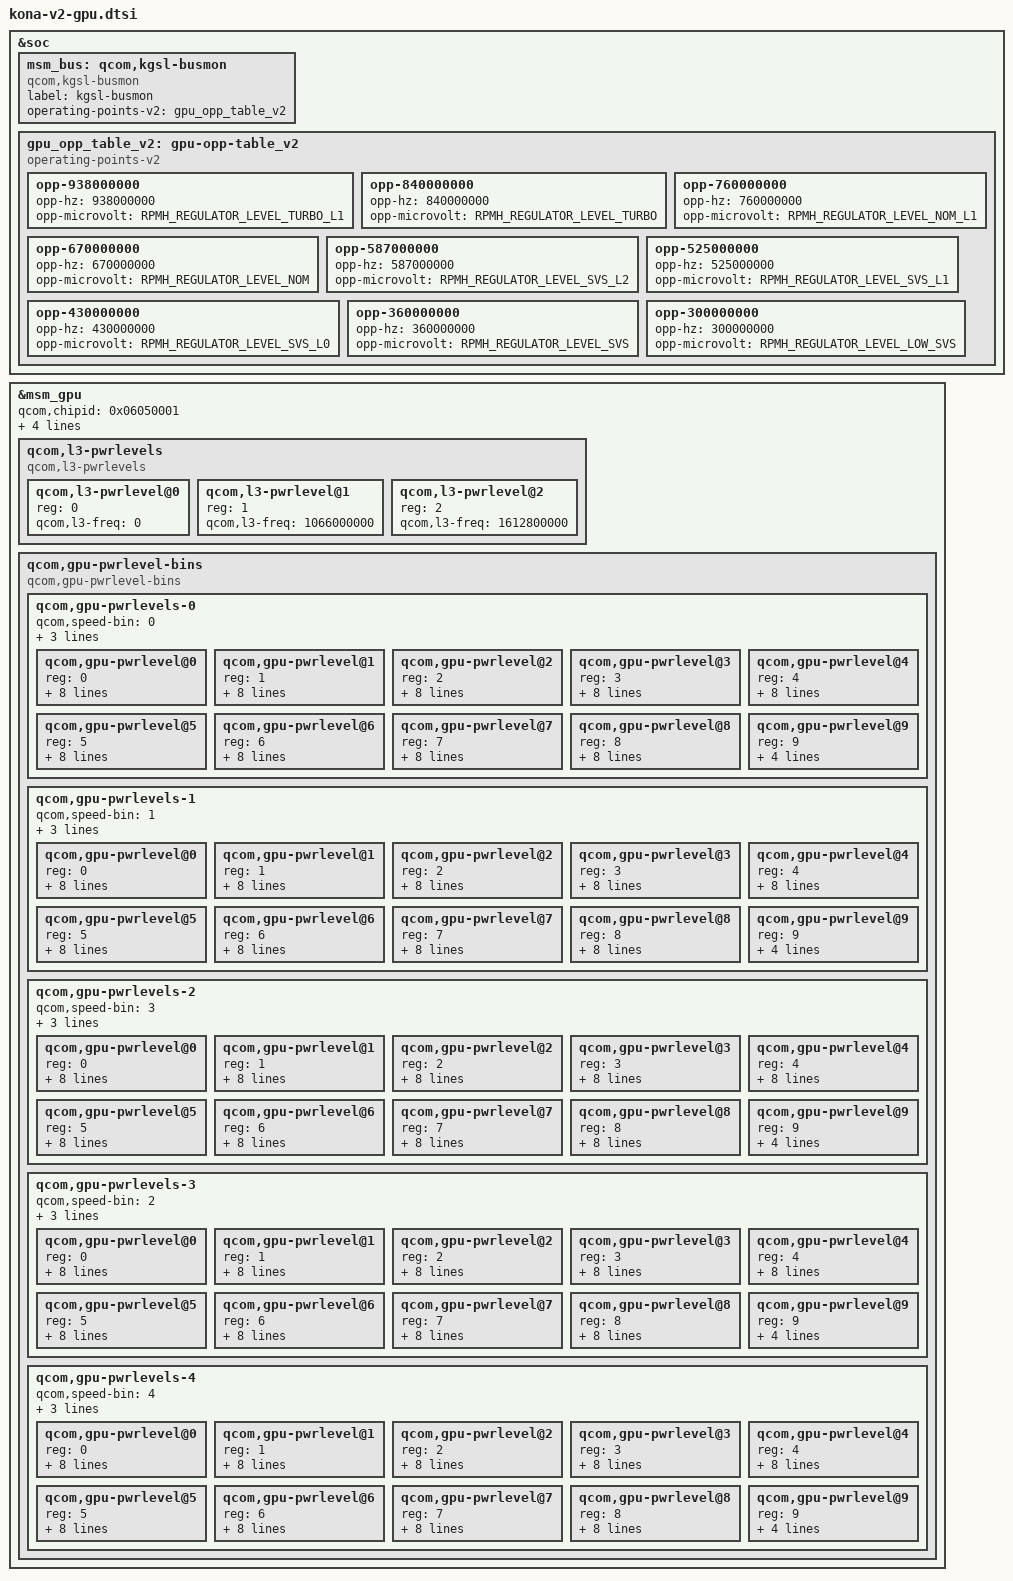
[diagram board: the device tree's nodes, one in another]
&soc {
	msm_bus: qcom,kgsl-busmon {
		label = "kgsl-busmon";
		compatible = "qcom,kgsl-busmon";
		operating-points-v2 = <&gpu_opp_table_v2>;
	};

	gpu_opp_table_v2: gpu-opp-table_v2 {
		compatible = "operating-points-v2";

		opp-938000000 {
			opp-hz = /bits/ 64 <938000000>;
			opp-microvolt = <RPMH_REGULATOR_LEVEL_TURBO_L1>;
		};
		opp-840000000 {
			opp-hz = /bits/ 64 <840000000>;
			opp-microvolt = <RPMH_REGULATOR_LEVEL_TURBO>;
		};
		opp-760000000 {
			opp-hz = /bits/ 64 <760000000>;
			opp-microvolt = <RPMH_REGULATOR_LEVEL_NOM_L1>;
		};
		opp-670000000 {
			opp-hz = /bits/ 64 <670000000>;
			opp-microvolt = <RPMH_REGULATOR_LEVEL_NOM>;
		};
		opp-587000000 {
			opp-hz = /bits/ 64 <587000000>;
			opp-microvolt = <RPMH_REGULATOR_LEVEL_SVS_L2>;
		};
		opp-525000000 {
			opp-hz = /bits/ 64 <525000000>;
			opp-microvolt = <RPMH_REGULATOR_LEVEL_SVS_L1>;
		};
		opp-430000000 {
			opp-hz = /bits/ 64 <430000000>;
			opp-microvolt = <RPMH_REGULATOR_LEVEL_SVS_L0>;
		};
		opp-360000000 {
			opp-hz = /bits/ 64 <360000000>;
			opp-microvolt = <RPMH_REGULATOR_LEVEL_SVS>;
		};
		opp-300000000 {
			opp-hz = /bits/ 64 <300000000>;
			opp-microvolt = <RPMH_REGULATOR_LEVEL_LOW_SVS>;
		};
	};
};

&msm_gpu {
	qcom,chipid = <0x06050001>;

	qcom,enable-ca-jump;
	qcom,ca-busy-penalty = <9000>;
	qcom,enable-midframe-timer;

	/* GPU OPP data */
	operating-points-v2 = <&gpu_opp_table_v2>;

	/delete-property/qcom,initial-pwrlevel;
	/delete-node/qcom,gpu-pwrlevels;
	/delete-node/qcom,l3-pwrlevels;

	/* L3 vote levels tuned for the higher Kona V2 GPU bins */
	qcom,l3-pwrlevels {
		#address-cells = <1>;
		#size-cells = <0>;
		compatible = "qcom,l3-pwrlevels";

		qcom,l3-pwrlevel@0 {
			reg = <0>;
			qcom,l3-freq = <0>;
		};

		qcom,l3-pwrlevel@1 {
			reg = <1>;
			qcom,l3-freq = <1066000000>;
		};

		qcom,l3-pwrlevel@2 {
			reg = <2>;
			qcom,l3-freq = <1612800000>;
		};
	};

	/* Power levels bins */
	qcom,gpu-pwrlevel-bins {
		compatible="qcom,gpu-pwrlevel-bins";
		#address-cells = <1>;
		#size-cells = <0>;

		qcom,gpu-pwrlevels-0 {
			#address-cells = <1>;
			#size-cells = <0>;
			qcom,speed-bin = <0>;
			/* Start and resume at the lowest non-zero GPU OPP. */
			qcom,initial-pwrlevel = <8>;
			qcom,throttle-pwrlevel = <0>;
			qcom,ca-target-pwrlevel = <1>;

			qcom,gpu-pwrlevel@0 {
				reg = <0>;
				qcom,gpu-freq = <938000000>;
				qcom,bus-freq-ddr7 = <13>;
				qcom,bus-min-ddr7 = <10>;
				qcom,bus-max-ddr7 = <13>;

				qcom,bus-freq-ddr8 = <13>;
				qcom,bus-min-ddr8 = <10>;
				qcom,bus-max-ddr8 = <13>;

				qcom,acd-level = <0x802b5ffd>;
			};

			qcom,gpu-pwrlevel@1 {
				reg = <1>;
				qcom,gpu-freq = <840000000>;
				qcom,bus-freq-ddr7 = <13>;
				qcom,bus-min-ddr7 = <10>;
				qcom,bus-max-ddr7 = <13>;

				qcom,bus-freq-ddr8 = <13>;
				qcom,bus-min-ddr8 = <10>;
				qcom,bus-max-ddr8 = <13>;

				qcom,acd-level = <0x802b5ffd>;
			};

			qcom,gpu-pwrlevel@2 {
				reg = <2>;
				qcom,gpu-freq = <760000000>;
				qcom,bus-freq-ddr7 = <13>;
				qcom,bus-min-ddr7 = <10>;
				qcom,bus-max-ddr7 = <13>;

				qcom,bus-freq-ddr8 = <13>;
				qcom,bus-min-ddr8 = <10>;
				qcom,bus-max-ddr8 = <13>;

				qcom,acd-level = <0x802b5ffd>;
			};

			qcom,gpu-pwrlevel@3 {
				reg = <3>;
				qcom,gpu-freq = <670000000>;
				qcom,bus-freq-ddr7 = <13>;
				qcom,bus-min-ddr7 = <10>;
				qcom,bus-max-ddr7 = <13>;

				qcom,bus-freq-ddr8 = <13>;
				qcom,bus-min-ddr8 = <10>;
				qcom,bus-max-ddr8 = <13>;

				qcom,acd-level = <0x802b5ffd>;
			};

			qcom,gpu-pwrlevel@4 {
				reg = <4>;
				qcom,gpu-freq = <587000000>;
				qcom,bus-freq-ddr7 = <12>;
				qcom,bus-min-ddr7 = <10>;
				qcom,bus-max-ddr7 = <13>;

				qcom,bus-freq-ddr8 = <12>;
				qcom,bus-min-ddr8 = <10>;
				qcom,bus-max-ddr8 = <13>;

				qcom,acd-level = <0x802b5ffd>;
			};

			qcom,gpu-pwrlevel@5 {
				reg = <5>;
				qcom,gpu-freq = <525000000>;
				qcom,bus-freq-ddr7 = <11>;
				qcom,bus-min-ddr7 = <9>;
				qcom,bus-max-ddr7 = <13>;

				qcom,bus-freq-ddr8 = <11>;
				qcom,bus-min-ddr8 = <9>;
				qcom,bus-max-ddr8 = <13>;

				qcom,acd-level = <0x802b5ffd>;
			};

			qcom,gpu-pwrlevel@6 {
				reg = <6>;
				qcom,gpu-freq = <430000000>;
				qcom,bus-freq-ddr7 = <10>;
				qcom,bus-min-ddr7 = <10>;
				qcom,bus-max-ddr7 = <12>;

				qcom,bus-freq-ddr8 = <10>;
				qcom,bus-min-ddr8 = <10>;
				qcom,bus-max-ddr8 = <12>;

				qcom,acd-level = <0xa02b5ffd>;
			};

			qcom,gpu-pwrlevel@7 {
				reg = <7>;
				qcom,gpu-freq = <360000000>;
				qcom,bus-freq-ddr7 = <10>;
				qcom,bus-min-ddr7 = <10>;
				qcom,bus-max-ddr7 = <12>;

				qcom,bus-freq-ddr8 = <10>;
				qcom,bus-min-ddr8 = <10>;
				qcom,bus-max-ddr8 = <12>;

				qcom,acd-level = <0xa02b5ffd>;
			};

			qcom,gpu-pwrlevel@8 {
				reg = <8>;
				qcom,gpu-freq = <300000000>;
				qcom,bus-freq-ddr7 = <9>;
				qcom,bus-min-ddr7 = <8>;
				qcom,bus-max-ddr7 = <11>;

				qcom,bus-freq-ddr8 = <9>;
				qcom,bus-min-ddr8 = <8>;
				qcom,bus-max-ddr8 = <11>;

				qcom,acd-level = <0xa02b5ffd>;
			};

			qcom,gpu-pwrlevel@9 {
				reg = <9>;
				qcom,gpu-freq = <0>;
				qcom,bus-freq = <1>;
				qcom,bus-min = <1>;
				qcom,bus-max = <1>;
			};
		};

		qcom,gpu-pwrlevels-1 {
			#address-cells = <1>;
			#size-cells = <0>;
			qcom,speed-bin = <1>;
			qcom,initial-pwrlevel = <8>;
			qcom,throttle-pwrlevel = <1>;
			qcom,ca-target-pwrlevel = <4>;

			qcom,gpu-pwrlevel@0 {
				reg = <0>;
				qcom,gpu-freq = <938000000>;
				qcom,bus-freq-ddr7 = <13>;
				qcom,bus-min-ddr7 = <11>;
				qcom,bus-max-ddr7 = <13>;

				qcom,bus-freq-ddr8 = <13>;
				qcom,bus-min-ddr8 = <11>;
				qcom,bus-max-ddr8 = <13>;

				qcom,acd-level = <0x802b5ffd>;
			};

			qcom,gpu-pwrlevel@1 {
				reg = <1>;
				qcom,gpu-freq = <840000000>;
				qcom,bus-freq-ddr7 = <13>;
				qcom,bus-min-ddr7 = <10>;
				qcom,bus-max-ddr7 = <13>;

				qcom,bus-freq-ddr8 = <13>;
				qcom,bus-min-ddr8 = <10>;
				qcom,bus-max-ddr8 = <13>;

				qcom,acd-level = <0x802b5ffd>;
			};

			qcom,gpu-pwrlevel@2 {
				reg = <2>;
				qcom,gpu-freq = <760000000>;
				qcom,bus-freq-ddr7 = <13>;
				qcom,bus-min-ddr7 = <10>;
				qcom,bus-max-ddr7 = <13>;

				qcom,bus-freq-ddr8 = <13>;
				qcom,bus-min-ddr8 = <10>;
				qcom,bus-max-ddr8 = <13>;

				qcom,acd-level = <0x802b5ffd>;
			};

			qcom,gpu-pwrlevel@3 {
				reg = <3>;
				qcom,gpu-freq = <670000000>;
				qcom,bus-freq-ddr7 = <13>;
				qcom,bus-min-ddr7 = <10>;
				qcom,bus-max-ddr7 = <13>;

				qcom,bus-freq-ddr8 = <13>;
				qcom,bus-min-ddr8 = <10>;
				qcom,bus-max-ddr8 = <13>;

				qcom,acd-level = <0x802b5ffd>;
			};

			qcom,gpu-pwrlevel@4 {
				reg = <4>;
				qcom,gpu-freq = <587000000>;
				qcom,bus-freq-ddr7 = <12>;
				qcom,bus-min-ddr7 = <10>;
				qcom,bus-max-ddr7 = <13>;

				qcom,bus-freq-ddr8 = <12>;
				qcom,bus-min-ddr8 = <10>;
				qcom,bus-max-ddr8 = <13>;

				qcom,acd-level = <0x802b5ffd>;
			};

			qcom,gpu-pwrlevel@5 {
				reg = <5>;
				qcom,gpu-freq = <525000000>;
				qcom,bus-freq-ddr7 = <11>;
				qcom,bus-min-ddr7 = <9>;
				qcom,bus-max-ddr7 = <13>;

				qcom,bus-freq-ddr8 = <11>;
				qcom,bus-min-ddr8 = <9>;
				qcom,bus-max-ddr8 = <13>;

				qcom,acd-level = <0x802b5ffd>;
			};

			qcom,gpu-pwrlevel@6 {
				reg = <6>;
				qcom,gpu-freq = <430000000>;
				qcom,bus-freq-ddr7 = <10>;
				qcom,bus-min-ddr7 = <10>;
				qcom,bus-max-ddr7 = <12>;

				qcom,bus-freq-ddr8 = <10>;
				qcom,bus-min-ddr8 = <10>;
				qcom,bus-max-ddr8 = <12>;

				qcom,acd-level = <0xa02b5ffd>;
			};

			qcom,gpu-pwrlevel@7 {
				reg = <7>;
				qcom,gpu-freq = <360000000>;
				qcom,bus-freq-ddr7 = <10>;
				qcom,bus-min-ddr7 = <10>;
				qcom,bus-max-ddr7 = <12>;

				qcom,bus-freq-ddr8 = <10>;
				qcom,bus-min-ddr8 = <10>;
				qcom,bus-max-ddr8 = <12>;

				qcom,acd-level = <0xa02b5ffd>;
			};

			qcom,gpu-pwrlevel@8 {
				reg = <8>;
				qcom,gpu-freq = <300000000>;
				qcom,bus-freq-ddr7 = <9>;
				qcom,bus-min-ddr7 = <8>;
				qcom,bus-max-ddr7 = <11>;

				qcom,bus-freq-ddr8 = <9>;
				qcom,bus-min-ddr8 = <8>;
				qcom,bus-max-ddr8 = <11>;

				qcom,acd-level = <0xa02b5ffd>;
			};

			qcom,gpu-pwrlevel@9 {
				reg = <9>;
				qcom,gpu-freq = <0>;
				qcom,bus-freq = <1>;
				qcom,bus-min = <1>;
				qcom,bus-max = <1>;
			};
		};

		qcom,gpu-pwrlevels-2 {
			#address-cells = <1>;
			#size-cells = <0>;
			qcom,speed-bin = <3>;
			qcom,initial-pwrlevel = <8>;
			qcom,throttle-pwrlevel = <1>;
			qcom,ca-target-pwrlevel = <4>;

			qcom,gpu-pwrlevel@0 {
				reg = <0>;
				qcom,gpu-freq = <938000000>;
				qcom,bus-freq-ddr7 = <13>;
				qcom,bus-min-ddr7 = <11>;
				qcom,bus-max-ddr7 = <13>;

				qcom,bus-freq-ddr8 = <13>;
				qcom,bus-min-ddr8 = <11>;
				qcom,bus-max-ddr8 = <13>;

				qcom,acd-level = <0x802b5ffd>;
			};

			qcom,gpu-pwrlevel@1 {
				reg = <1>;
				qcom,gpu-freq = <840000000>;
				qcom,bus-freq-ddr7 = <13>;
				qcom,bus-min-ddr7 = <10>;
				qcom,bus-max-ddr7 = <13>;

				qcom,bus-freq-ddr8 = <13>;
				qcom,bus-min-ddr8 = <10>;
				qcom,bus-max-ddr8 = <13>;

				qcom,acd-level = <0x802b5ffd>;
			};

			qcom,gpu-pwrlevel@2 {
				reg = <2>;
				qcom,gpu-freq = <760000000>;
				qcom,bus-freq-ddr7 = <13>;
				qcom,bus-min-ddr7 = <10>;
				qcom,bus-max-ddr7 = <13>;

				qcom,bus-freq-ddr8 = <13>;
				qcom,bus-min-ddr8 = <10>;
				qcom,bus-max-ddr8 = <13>;

				qcom,acd-level = <0x802b5ffd>;
			};

			qcom,gpu-pwrlevel@3 {
				reg = <3>;
				qcom,gpu-freq = <670000000>;
				qcom,bus-freq-ddr7 = <13>;
				qcom,bus-min-ddr7 = <10>;
				qcom,bus-max-ddr7 = <13>;

				qcom,bus-freq-ddr8 = <13>;
				qcom,bus-min-ddr8 = <10>;
				qcom,bus-max-ddr8 = <13>;

				qcom,acd-level = <0x802b5ffd>;
			};

			qcom,gpu-pwrlevel@4 {
				reg = <4>;
				qcom,gpu-freq = <587000000>;
				qcom,bus-freq-ddr7 = <12>;
				qcom,bus-min-ddr7 = <10>;
				qcom,bus-max-ddr7 = <13>;

				qcom,bus-freq-ddr8 = <12>;
				qcom,bus-min-ddr8 = <10>;
				qcom,bus-max-ddr8 = <13>;

				qcom,acd-level = <0x802b5ffd>;
			};

			qcom,gpu-pwrlevel@5 {
				reg = <5>;
				qcom,gpu-freq = <525000000>;
				qcom,bus-freq-ddr7 = <11>;
				qcom,bus-min-ddr7 = <9>;
				qcom,bus-max-ddr7 = <13>;

				qcom,bus-freq-ddr8 = <11>;
				qcom,bus-min-ddr8 = <9>;
				qcom,bus-max-ddr8 = <13>;

				qcom,acd-level = <0x802b5ffd>;
			};

			qcom,gpu-pwrlevel@6 {
				reg = <6>;
				qcom,gpu-freq = <430000000>;
				qcom,bus-freq-ddr7 = <10>;
				qcom,bus-min-ddr7 = <10>;
				qcom,bus-max-ddr7 = <12>;

				qcom,bus-freq-ddr8 = <10>;
				qcom,bus-min-ddr8 = <10>;
				qcom,bus-max-ddr8 = <12>;

				qcom,acd-level = <0xa02b5ffd>;
			};

			qcom,gpu-pwrlevel@7 {
				reg = <7>;
				qcom,gpu-freq = <360000000>;
				qcom,bus-freq-ddr7 = <10>;
				qcom,bus-min-ddr7 = <10>;
				qcom,bus-max-ddr7 = <12>;

				qcom,bus-freq-ddr8 = <10>;
				qcom,bus-min-ddr8 = <10>;
				qcom,bus-max-ddr8 = <12>;

				qcom,acd-level = <0xa02b5ffd>;
			};

			qcom,gpu-pwrlevel@8 {
				reg = <8>;
				qcom,gpu-freq = <300000000>;
				qcom,bus-freq-ddr7 = <9>;
				qcom,bus-min-ddr7 = <8>;
				qcom,bus-max-ddr7 = <11>;

				qcom,bus-freq-ddr8 = <9>;
				qcom,bus-min-ddr8 = <8>;
				qcom,bus-max-ddr8 = <11>;

				qcom,acd-level = <0xa02b5ffd>;
			};

			qcom,gpu-pwrlevel@9 {
				reg = <9>;
				qcom,gpu-freq = <0>;
				qcom,bus-freq = <1>;
				qcom,bus-min = <1>;
				qcom,bus-max = <1>;
			};
		};

		qcom,gpu-pwrlevels-3 {
			#address-cells = <1>;
			#size-cells = <0>;
			qcom,speed-bin = <2>;
			qcom,initial-pwrlevel = <8>;
			qcom,throttle-pwrlevel = <1>;
			qcom,ca-target-pwrlevel = <4>;

			qcom,gpu-pwrlevel@0 {
				reg = <0>;
				qcom,gpu-freq = <938000000>;
				qcom,bus-freq-ddr7 = <13>;
				qcom,bus-min-ddr7 = <11>;
				qcom,bus-max-ddr7 = <13>;

				qcom,bus-freq-ddr8 = <13>;
				qcom,bus-min-ddr8 = <11>;
				qcom,bus-max-ddr8 = <13>;

				qcom,acd-level = <0x802b5ffd>;
			};

			qcom,gpu-pwrlevel@1 {
				reg = <1>;
				qcom,gpu-freq = <840000000>;
				qcom,bus-freq-ddr7 = <13>;
				qcom,bus-min-ddr7 = <10>;
				qcom,bus-max-ddr7 = <13>;

				qcom,bus-freq-ddr8 = <13>;
				qcom,bus-min-ddr8 = <10>;
				qcom,bus-max-ddr8 = <13>;

				qcom,acd-level = <0x802b5ffd>;
			};

			qcom,gpu-pwrlevel@2 {
				reg = <2>;
				qcom,gpu-freq = <760000000>;
				qcom,bus-freq-ddr7 = <13>;
				qcom,bus-min-ddr7 = <10>;
				qcom,bus-max-ddr7 = <13>;

				qcom,bus-freq-ddr8 = <13>;
				qcom,bus-min-ddr8 = <10>;
				qcom,bus-max-ddr8 = <13>;

				qcom,acd-level = <0x802b5ffd>;
			};

			qcom,gpu-pwrlevel@3 {
				reg = <3>;
				qcom,gpu-freq = <670000000>;
				qcom,bus-freq-ddr7 = <13>;
				qcom,bus-min-ddr7 = <10>;
				qcom,bus-max-ddr7 = <13>;

				qcom,bus-freq-ddr8 = <13>;
				qcom,bus-min-ddr8 = <10>;
				qcom,bus-max-ddr8 = <13>;

				qcom,acd-level = <0x802b5ffd>;
			};

			qcom,gpu-pwrlevel@4 {
				reg = <4>;
				qcom,gpu-freq = <587000000>;
				qcom,bus-freq-ddr7 = <12>;
				qcom,bus-min-ddr7 = <10>;
				qcom,bus-max-ddr7 = <13>;

				qcom,bus-freq-ddr8 = <12>;
				qcom,bus-min-ddr8 = <10>;
				qcom,bus-max-ddr8 = <13>;

				qcom,acd-level = <0x802b5ffd>;
			};

			qcom,gpu-pwrlevel@5 {
				reg = <5>;
				qcom,gpu-freq = <525000000>;
				qcom,bus-freq-ddr7 = <11>;
				qcom,bus-min-ddr7 = <9>;
				qcom,bus-max-ddr7 = <13>;

				qcom,bus-freq-ddr8 = <11>;
				qcom,bus-min-ddr8 = <9>;
				qcom,bus-max-ddr8 = <13>;

				qcom,acd-level = <0x802b5ffd>;
			};

			qcom,gpu-pwrlevel@6 {
				reg = <6>;
				qcom,gpu-freq = <430000000>;
				qcom,bus-freq-ddr7 = <10>;
				qcom,bus-min-ddr7 = <10>;
				qcom,bus-max-ddr7 = <12>;

				qcom,bus-freq-ddr8 = <10>;
				qcom,bus-min-ddr8 = <10>;
				qcom,bus-max-ddr8 = <12>;

				qcom,acd-level = <0xa02b5ffd>;
			};

			qcom,gpu-pwrlevel@7 {
				reg = <7>;
				qcom,gpu-freq = <360000000>;
				qcom,bus-freq-ddr7 = <10>;
				qcom,bus-min-ddr7 = <10>;
				qcom,bus-max-ddr7 = <12>;

				qcom,bus-freq-ddr8 = <10>;
				qcom,bus-min-ddr8 = <10>;
				qcom,bus-max-ddr8 = <12>;

				qcom,acd-level = <0xa02b5ffd>;
			};

			qcom,gpu-pwrlevel@8 {
				reg = <8>;
				qcom,gpu-freq = <300000000>;
				qcom,bus-freq-ddr7 = <9>;
				qcom,bus-min-ddr7 = <8>;
				qcom,bus-max-ddr7 = <11>;

				qcom,bus-freq-ddr8 = <9>;
				qcom,bus-min-ddr8 = <8>;
				qcom,bus-max-ddr8 = <11>;

				qcom,acd-level = <0xa02b5ffd>;
			};

			qcom,gpu-pwrlevel@9 {
				reg = <9>;
				qcom,gpu-freq = <0>;
				qcom,bus-freq = <1>;
				qcom,bus-min = <1>;
				qcom,bus-max = <1>;
			};
		};

		qcom,gpu-pwrlevels-4 {
			#address-cells = <1>;
			#size-cells = <0>;
			qcom,speed-bin = <4>;
			qcom,initial-pwrlevel = <8>;
			qcom,throttle-pwrlevel = <1>;
			qcom,ca-target-pwrlevel = <4>;

			qcom,gpu-pwrlevel@0 {
				reg = <0>;
				qcom,gpu-freq = <938000000>;
				qcom,bus-freq-ddr7 = <13>;
				qcom,bus-min-ddr7 = <11>;
				qcom,bus-max-ddr7 = <13>;

				qcom,bus-freq-ddr8 = <13>;
				qcom,bus-min-ddr8 = <11>;
				qcom,bus-max-ddr8 = <13>;

				qcom,acd-level = <0x802b5ffd>;
			};

			qcom,gpu-pwrlevel@1 {
				reg = <1>;
				qcom,gpu-freq = <840000000>;
				qcom,bus-freq-ddr7 = <13>;
				qcom,bus-min-ddr7 = <10>;
				qcom,bus-max-ddr7 = <13>;

				qcom,bus-freq-ddr8 = <13>;
				qcom,bus-min-ddr8 = <10>;
				qcom,bus-max-ddr8 = <13>;

				qcom,acd-level = <0x802b5ffd>;
			};

			qcom,gpu-pwrlevel@2 {
				reg = <2>;
				qcom,gpu-freq = <760000000>;
				qcom,bus-freq-ddr7 = <13>;
				qcom,bus-min-ddr7 = <10>;
				qcom,bus-max-ddr7 = <13>;

				qcom,bus-freq-ddr8 = <13>;
				qcom,bus-min-ddr8 = <10>;
				qcom,bus-max-ddr8 = <13>;

				qcom,acd-level = <0x802b5ffd>;
			};

			qcom,gpu-pwrlevel@3 {
				reg = <3>;
				qcom,gpu-freq = <670000000>;
				qcom,bus-freq-ddr7 = <13>;
				qcom,bus-min-ddr7 = <10>;
				qcom,bus-max-ddr7 = <13>;

				qcom,bus-freq-ddr8 = <13>;
				qcom,bus-min-ddr8 = <10>;
				qcom,bus-max-ddr8 = <13>;

				qcom,acd-level = <0x802b5ffd>;
			};

			qcom,gpu-pwrlevel@4 {
				reg = <4>;
				qcom,gpu-freq = <587000000>;
				qcom,bus-freq-ddr7 = <12>;
				qcom,bus-min-ddr7 = <10>;
				qcom,bus-max-ddr7 = <13>;

				qcom,bus-freq-ddr8 = <12>;
				qcom,bus-min-ddr8 = <10>;
				qcom,bus-max-ddr8 = <13>;

				qcom,acd-level = <0x802b5ffd>;
			};

			qcom,gpu-pwrlevel@5 {
				reg = <5>;
				qcom,gpu-freq = <525000000>;
				qcom,bus-freq-ddr7 = <11>;
				qcom,bus-min-ddr7 = <9>;
				qcom,bus-max-ddr7 = <13>;

				qcom,bus-freq-ddr8 = <11>;
				qcom,bus-min-ddr8 = <9>;
				qcom,bus-max-ddr8 = <13>;

				qcom,acd-level = <0x802b5ffd>;
			};

			qcom,gpu-pwrlevel@6 {
				reg = <6>;
				qcom,gpu-freq = <430000000>;
				qcom,bus-freq-ddr7 = <10>;
				qcom,bus-min-ddr7 = <10>;
				qcom,bus-max-ddr7 = <12>;

				qcom,bus-freq-ddr8 = <10>;
				qcom,bus-min-ddr8 = <10>;
				qcom,bus-max-ddr8 = <12>;

				qcom,acd-level = <0xa02b5ffd>;
			};

			qcom,gpu-pwrlevel@7 {
				reg = <7>;
				qcom,gpu-freq = <360000000>;
				qcom,bus-freq-ddr7 = <10>;
				qcom,bus-min-ddr7 = <10>;
				qcom,bus-max-ddr7 = <12>;

				qcom,bus-freq-ddr8 = <10>;
				qcom,bus-min-ddr8 = <10>;
				qcom,bus-max-ddr8 = <12>;

				qcom,acd-level = <0xa02b5ffd>;
			};

			qcom,gpu-pwrlevel@8 {
				reg = <8>;
				qcom,gpu-freq = <300000000>;
				qcom,bus-freq-ddr7 = <9>;
				qcom,bus-min-ddr7 = <8>;
				qcom,bus-max-ddr7 = <11>;

				qcom,bus-freq-ddr8 = <9>;
				qcom,bus-min-ddr8 = <8>;
				qcom,bus-max-ddr8 = <11>;

				qcom,acd-level = <0xa02b5ffd>;
			};

			qcom,gpu-pwrlevel@9 {
				reg = <9>;
				qcom,gpu-freq = <0>;
				qcom,bus-freq = <1>;
				qcom,bus-min = <1>;
				qcom,bus-max = <1>;
			};
		};
	};
};

